AUTOSAR XML (schema 00048)
package /SecurityArchitecture/ComponentTypes
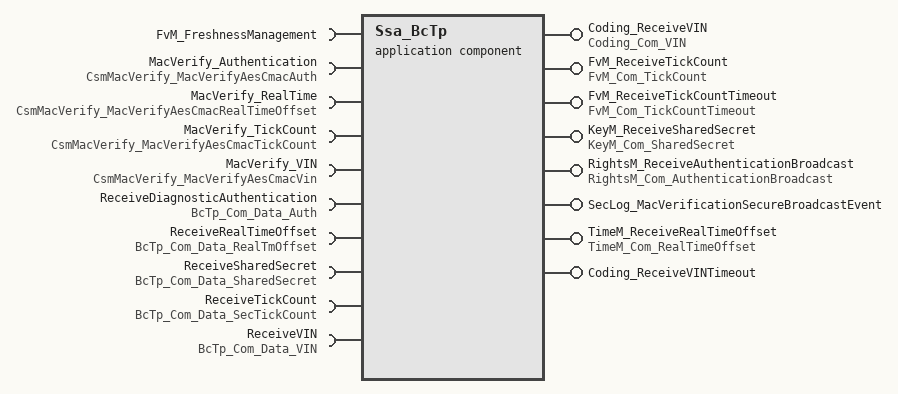
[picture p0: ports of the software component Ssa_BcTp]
  application sw component type Ssa_BcTp
    7 x provide port:
      Coding_ReceiveVIN: nonqueued-sender-com-spec{data-element=VIN, init-value=constant-reference=Ssa_Init_VIN}, provided-interface=Coding_Com_VIN  # Configuration Variant(s): Not in VSM.
      FvM_ReceiveTickCount: nonqueued-sender-com-spec{data-element=tickCount, init-value=constant-reference=Ssa_Init_Zero_6Byte}, provided-interface=FvM_Com_TickCount  # Configuration Variant(s): Not in VSM.
      FvM_ReceiveTickCountTimeout: nonqueued-sender-com-spec{data-element=state, init-value=0}, provided-interface=FvM_Com_TickCountTimeout  # Configuration Variant(s): Not in VSM.
      KeyM_ReceiveSharedSecret: nonqueued-sender-com-spec{data-element=sharedSecret, init-value=constant-reference=Ssa_Init_Zero_32Byte}, provided-interface=KeyM_Com_SharedSecret  # Configuration Variant(s): Not in VSM.
      RightsM_ReceiveAuthenticationBroadcast: nonqueued-sender-com-spec{data-element=authentication, init-value=constant-reference=Ssa_Init_Zero_20Byte}, provided-interface=RightsM_Com_AuthenticationBroadcast  # Configuration Variant(s): Not in VSM.
      SecLog_MacVerificationSecureBroadcastEvent: nonqueued-sender-com-spec{data-element=verificationStatus, init-value=constant-reference=Ssa_Init_SecOcVerificationState}, provided-interface=SecLog_MacVerificationSecureBroadcastEvent  # Configuration Variant(s): Not in VSM.
      TimeM_ReceiveRealTimeOffset: nonqueued-sender-com-spec{data-element=realTimeOffset, init-value=constant-reference=Ssa_Init_Zero_12Byte}, provided-interface=TimeM_Com_RealTimeOffset  # Configuration Variant(s): Not in VSM.
    10 x require port:
      FvM_FreshnessManagement: required-com-specs=[GetRxFreshness, GetTxFreshness], required-interface=FvM_FreshnessManagement
      MacVerify_Authentication: client-com-spec=MacVerify, required-interface=CsmMacVerify_MacVerifyAesCmacAuth  # Verifies the mac for a received diagnostic authentication broadcast. Connect to a Csm Mac Verify Job which uses the corresponding key of this broadcast. Configuration Variant(s): Not in VSM.
      MacVerify_RealTime: client-com-spec=MacVerify, required-interface=CsmMacVerify_MacVerifyAesCmacRealTimeOffset  # Verifies the mac for a received real time offset broadcast. Connect to a Csm Mac Verify Job which uses the corresponding key of this broadcast. Configuration Variant(s): Not in VSM.
      MacVerify_TickCount: client-com-spec=MacVerify, required-interface=CsmMacVerify_MacVerifyAesCmacTickCount  # Verifies the mac for a received tick count broadcast. Connect to a Csm Mac Verify Job which uses the corresponding key of this broadcast. Configuration Variant(s): Not in VSM.
      MacVerify_VIN: client-com-spec=MacVerify, required-interface=CsmMacVerify_MacVerifyAesCmacVin  # Verifies the mac for a received VIN broadcast. Connect to a Csm Mac Verify Job which uses the corresponding key of this broadcast. Configuration Variant(s): Not in VSM.
      ReceiveDiagnosticAuthentication: nonqueued-receiver-com-spec{data-element=VSS_TP_Auth_ST3, filter=data-filter-type=ALWAYS, init-value=constant-reference=Ssa_Init_ComSignal_8Byte}, required-interface=BcTp_Com_Data_Auth  # Configuration Variant(s): Not in VSM.
      ReceiveRealTimeOffset: nonqueued-receiver-com-spec{data-element=VSS_TP_RealTmOffset_ST3, filter=data-filter-type=ALWAYS, init-value=constant-reference=Ssa_Init_ComSignal_8Byte}, required-interface=BcTp_Com_Data_RealTmOffset  # Configuration Variant(s): Not in VSM.
      ReceiveSharedSecret: nonqueued-receiver-com-spec{data-element=VSS_TP_SharedSecret_ST3, filter=data-filter-type=ALWAYS, init-value=constant-reference=Ssa_Init_ComSignal_8Byte}, required-interface=BcTp_Com_Data_SharedSecret  # Configuration Variant(s): Not in VSM.
      ReceiveTickCount: nonqueued-receiver-com-spec{data-element=VSS_TP_SecTickCount_ST3, alive-timeout=1, filter=data-filter-type=ALWAYS, init-value=constant-reference=Ssa_Init_ComSignal_8Byte}, required-interface=BcTp_Com_Data_SecTickCount  # Configuration Variant(s): Not in VSM.
      ReceiveVIN: nonqueued-receiver-com-spec{data-element=VSS_TP_VIN_ST3, alive-timeout=5, filter=data-filter-type=ALWAYS, init-value=constant-reference=Ssa_Init_ComSignal_8Byte}, required-interface=BcTp_Com_Data_VIN  # Configuration Variant(s): Not in VSM.
    provide port Coding_ReceiveVINTimeout: nonqueued-sender-com-spec{data-element=state, init-value=0}, provided-interface=Coding_ReceiveVINTimeout  # Configuration Variant(s): Not in VSM.
    behavior Ssa_BcTp_InternalBehavior
      init event BcTp_InitEvent: start-on-event=Ssa_BcTp_Init
      4 x data received event:
        DRT_Ssa_BcTp_ReceiveDiagnosticAuthentication_ReceiveDiagnosticAuthentication_VSS_TP_Auth_ST3: start-on-event=Ssa_BcTp_ReceiveDiagnosticAuthentication, data=ReceiveDiagnosticAuthentication.VSS_TP_Auth_ST3
        DRT_Ssa_BcTp_ReceiveRealTimeOffset_ReceiveRealTimeOffset_VSS_TP_RealTmOffset_ST3: start-on-event=Ssa_BcTp_ReceiveRealTimeOffset, data=ReceiveRealTimeOffset.VSS_TP_RealTmOffset_ST3
        DRT_Ssa_BcTp_ReceiveSharedSecret_ReceiveSharedSecret_VSS_TP_SharedSecret_ST3: start-on-event=Ssa_BcTp_ReceiveSharedSecret, data=ReceiveSharedSecret.VSS_TP_SharedSecret_ST3
        DRT_Ssa_BcTp_ReceiveTickCount_ReceiveTickCount_VSS_TP_SecTickCount_ST3: start-on-event=Ssa_BcTp_ReceiveTickCount, data=ReceiveTickCount.VSS_TP_SecTickCount_ST3
      data receive error event DRET_Runnable_ReceiveTickCount_VSS_TP_SecTickCount_ST3: start-on-event=Ssa_BcTp_ReceiveTickCountTimeout, data=ReceiveTickCount.VSS_TP_SecTickCount_ST3
      data received event DRT_Ssa_BcTp_ReceiveVIN_ReceiveVIN_VSS_TP_VIN_ST3: start-on-event=Ssa_BcTp_ReceiveVIN, data=ReceiveVIN.VSS_TP_VIN_ST3
      data receive error event DRET_Ssa_BcTp_ReceiveVINTimeout_ReceiveVIN_VSS_TP_VIN_ST3: start-on-event=Ssa_BcTp_ReceiveVINTimeout, data=ReceiveVIN.VSS_TP_VIN_ST3
      port-api-options:
        enable-take-address=false, error-handling=NO-TRANSFORMER-ERROR-HANDLING, indirect-api=false, port=Coding_ReceiveVIN
        enable-take-address=false, error-handling=NO-TRANSFORMER-ERROR-HANDLING, indirect-api=false, port=FvM_FreshnessManagement
        enable-take-address=false, error-handling=NO-TRANSFORMER-ERROR-HANDLING, indirect-api=false, port=FvM_ReceiveTickCount
        enable-take-address=false, error-handling=NO-TRANSFORMER-ERROR-HANDLING, indirect-api=false, port=KeyM_ReceiveSharedSecret
        enable-take-address=true, error-handling=NO-TRANSFORMER-ERROR-HANDLING, indirect-api=false, port=MacVerify_Authentication
        enable-take-address=true, error-handling=NO-TRANSFORMER-ERROR-HANDLING, indirect-api=false, port=MacVerify_RealTime
        enable-take-address=true, error-handling=NO-TRANSFORMER-ERROR-HANDLING, indirect-api=false, port=MacVerify_TickCount
        enable-take-address=true, error-handling=NO-TRANSFORMER-ERROR-HANDLING, indirect-api=false, port=MacVerify_VIN
        enable-take-address=false, error-handling=NO-TRANSFORMER-ERROR-HANDLING, indirect-api=false, port=ReceiveDiagnosticAuthentication
        enable-take-address=false, error-handling=NO-TRANSFORMER-ERROR-HANDLING, indirect-api=false, port=ReceiveRealTimeOffset
        enable-take-address=false, error-handling=NO-TRANSFORMER-ERROR-HANDLING, indirect-api=false, port=ReceiveSharedSecret
        enable-take-address=false, error-handling=NO-TRANSFORMER-ERROR-HANDLING, indirect-api=false, port=ReceiveTickCount
        enable-take-address=false, error-handling=NO-TRANSFORMER-ERROR-HANDLING, indirect-api=false, port=RightsM_ReceiveAuthenticationBroadcast
        enable-take-address=false, error-handling=NO-TRANSFORMER-ERROR-HANDLING, indirect-api=false, port=TimeM_ReceiveRealTimeOffset
      8 x runnable:
        Ssa_BcTp_Init
        Ssa_BcTp_ReceiveDiagnosticAuthentication  # Configuration Variant(s): Not in VSM.
          data-receive-point-by-arguments:
            access REC_ReceiveDiagnosticAuthentication_VSS_TP_Auth_ST3: accessed-variable=ReceiveDiagnosticAuthentication.VSS_TP_Auth_ST3
          data-send-points:
            access SEND_BcTp_VerificationStatusService_verificationStatus: accessed-variable=SecLog_MacVerificationSecureBroadcastEvent.verificationStatus
            access SEND_RightsM_ReceiveAuthenticationBroadcast_authentication: accessed-variable=RightsM_ReceiveAuthenticationBroadcast.authentication
          sync call SC_MacVerify_Authentication_MacVerify: operation=MacVerify_Authentication.MacVerify
          sync call SC_TimeM_FreshnessManagement_GetRxFreshness: operation=FvM_FreshnessManagement.GetRxFreshness
        Ssa_BcTp_ReceiveRealTimeOffset  # Configuration Variant(s): Not in VSM.
          data-receive-point-by-arguments:
            access REC_ReceiveRealTimeOffset_VSS_TP_RealTmOffset_ST3: accessed-variable=ReceiveRealTimeOffset.VSS_TP_RealTmOffset_ST3
          data-send-points:
            access SEND_BcTp_VerificationStatusService_verificationStatus: accessed-variable=SecLog_MacVerificationSecureBroadcastEvent.verificationStatus
            access SEND_TimeM_ReceiveRealTimeOffset_realTimeOffset: accessed-variable=TimeM_ReceiveRealTimeOffset.realTimeOffset
          sync call SC_MacVerify_RealTime_MacVerify: operation=MacVerify_RealTime.MacVerify
          sync call SC_TimeM_FreshnessManagement_GetRxFreshness: operation=FvM_FreshnessManagement.GetRxFreshness
        Ssa_BcTp_ReceiveSharedSecret  # Configuration Variant(s): Not in VSM.
          data-receive-point-by-arguments:
            access REC_ReceiveSharedSecret_VSS_TP_SharedSecret_ST3: accessed-variable=ReceiveSharedSecret.VSS_TP_SharedSecret_ST3
          data-send-points:
            access SEND_KeyM_ReceiveSharedSecret_sharedSecret: accessed-variable=KeyM_ReceiveSharedSecret.sharedSecret
          sync call SC_TimeM_FreshnessManagement_GetRxFreshness: operation=FvM_FreshnessManagement.GetRxFreshness
        Ssa_BcTp_ReceiveTickCount  # Configuration Variant(s): Not in VSM.
          data-receive-point-by-arguments:
            access REC_ReceiveTickCount_VSS_TP_SecTickCount_ST3: accessed-variable=ReceiveTickCount.VSS_TP_SecTickCount_ST3
          data-send-points:
            access SEND_BcTp_VerificationStatusService_verificationStatus: accessed-variable=SecLog_MacVerificationSecureBroadcastEvent.verificationStatus
            access SEND_TimeM_ReceiveTickCount_tickCount: accessed-variable=FvM_ReceiveTickCount.tickCount
          sync call SC_MacVerify_TickCount_MacVerify: operation=MacVerify_TickCount.MacVerify
        Ssa_BcTp_ReceiveTickCountTimeout  # Configuration Variant(s): Not in VSM.
          data-send-points:
            access SEND_FvM_ReceiveTickCountTimeout_state: accessed-variable=FvM_ReceiveTickCountTimeout.state
        Ssa_BcTp_ReceiveVIN  # Configuration Variant(s): Not in VSM.
          data-receive-point-by-arguments:
            access REC_ReceiveVIN_VSS_TP_VIN_ST3: accessed-variable=ReceiveVIN.VSS_TP_VIN_ST3
          data-send-points:
            access SEND_BcTp_VerificationStatusService_verificationStatus: accessed-variable=SecLog_MacVerificationSecureBroadcastEvent.verificationStatus
            access SEND_Coding_ReceiveVIN_VIN: accessed-variable=Coding_ReceiveVIN.VIN
          sync call SC_MacVerify_VIN_MacVerify: operation=MacVerify_VIN.MacVerify
          sync call SC_TimeM_FreshnessManagement_GetRxFreshness: operation=FvM_FreshnessManagement.GetRxFreshness
        Ssa_BcTp_ReceiveVINTimeout  # Configuration Variant(s): Not in VSM.
          data-send-points:
            access SEND_Coding_ReceiveVINTimeout_state: accessed-variable=Coding_ReceiveVINTimeout.state
  swc implementation Ssa_BcTp_Implementation: behavior=Ssa_BcTp_InternalBehavior
    code-descriptors:
      code Default: artifact-descriptors=autosar-engineering-object=category=SWSRC
